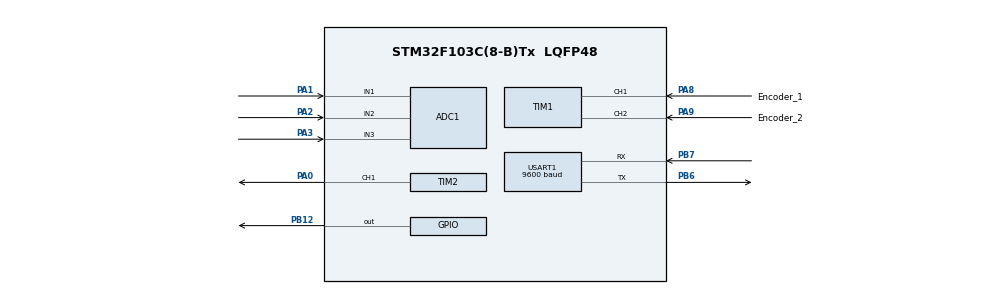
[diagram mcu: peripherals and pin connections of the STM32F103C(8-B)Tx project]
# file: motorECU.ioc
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ADC1.Channel-1\#ChannelRegularConversion=ADC_CHANNEL_1
ADC1.Channel-2\#ChannelRegularConversion=ADC_CHANNEL_2
ADC1.Channel-3\#ChannelRegularConversion=ADC_CHANNEL_3
ADC1.ContinuousConvMode=DISABLE
ADC1.NbrOfConversion=3
ADC1.NbrOfConversionFlag=1
ADC1.Rank-1\#ChannelRegularConversion=1
ADC1.Rank-2\#ChannelRegularConversion=2
ADC1.Rank-3\#ChannelRegularConversion=3
ADC1.SamplingTime-1\#ChannelRegularConversion=ADC_SAMPLETIME_1CYCLE_5
ADC1.SamplingTime-2\#ChannelRegularConversion=ADC_SAMPLETIME_1CYCLE_5
ADC1.SamplingTime-3\#ChannelRegularConversion=ADC_SAMPLETIME_1CYCLE_5
ADC1.master=1
Dma.ADC1.0.Direction=DMA_PERIPH_TO_MEMORY
Dma.ADC1.0.Instance=DMA1_Channel1
Dma.ADC1.0.MemDataAlignment=DMA_MDATAALIGN_WORD
Dma.ADC1.0.MemInc=DMA_MINC_ENABLE
Dma.ADC1.0.Mode=DMA_CIRCULAR
Dma.ADC1.0.PeriphDataAlignment=DMA_PDATAALIGN_WORD
Dma.ADC1.0.PeriphInc=DMA_PINC_DISABLE
Dma.ADC1.0.Priority=DMA_PRIORITY_LOW
Dma.Request0=ADC1
Mcu.Family=STM32F1
Mcu.Name=STM32F103C(8-B)Tx
Mcu.Package=LQFP48
NVIC.DMA1_Channel1_IRQn=true\:0\:0\:false\:false\:true\:false\:true\:true
NVIC.PriorityGroup=NVIC_PRIORITYGROUP_4
PA0-WKUP.Signal=S_TIM2_CH1_ETR
PA1.Signal=ADCx_IN1
PA13.Mode=Serial_Wire
PA13.Signal=SYS_JTMS-SWDIO
PA14.Mode=Serial_Wire
PA14.Signal=SYS_JTCK-SWCLK
PA2.Signal=ADCx_IN2
PA3.Signal=ADCx_IN3
PA8.GPIO_Label=Encoder_1
PA8.Signal=S_TIM1_CH1
PA9.GPIO_Label=Encoder_2
PA9.Signal=S_TIM1_CH2
PB12.Signal=GPIO_Output
PB6.Mode=Asynchronous
PB6.Signal=USART1_TX
PB7.Mode=Asynchronous
PB7.Signal=USART1_RX
ProjectManager.HeapSize=0x200
ProjectManager.StackSize=0x400
ProjectManager.TargetToolchain=STM32CubeIDE
RCC.APB1Freq_Value=8000000
RCC.APB2Freq_Value=8000000
SH.ADCx_IN1.0=ADC1_IN1,IN1
SH.ADCx_IN2.0=ADC1_IN2,IN2
SH.ADCx_IN3.0=ADC1_IN3,IN3
SH.S_TIM1_CH1.0=TIM1_CH1,Encoder_Interface
SH.S_TIM1_CH2.0=TIM1_CH2,Encoder_Interface
SH.S_TIM2_CH1_ETR.0=TIM2_CH1,PWM Generation1 CH1
TIM2.Channel-PWM\ Generation1\ CH1=TIM_CHANNEL_1
USART1.BaudRate=9600
USART1.VirtualMode=VM_ASYNC
VP_TIM2_VS_ClockSourceINT.Mode=Internal
board=custom

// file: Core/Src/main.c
/* USER CODE BEGIN Header */
/**
  ******************************************************************************
  * @file           : main.c
  * @brief          : Main program body
  ******************************************************************************
  * @attention
  *
  * Copyright (c) 2024 STMicroelectronics.
  * All rights reserved.
  *
  * This software is licensed under terms that can be found in the LICENSE file
  * in the root directory of this software component.
  * If no LICENSE file comes with this software, it is provided AS-IS.
  *
  ******************************************************************************
  */
/* USER CODE END Header */
#include "main.h"

/* USER CODE BEGIN Includes */
#include "DC_MOTOR.h"
#include "Pedal.h"

#include "Encoder.h"
#include "Comm.h"
#include <stdio.h>
#include "Indicators.h"

#include "Schedular.h"

/* USER CODE END Includes */

ADC_HandleTypeDef hadc1;
DMA_HandleTypeDef hdma_adc1;

TIM_HandleTypeDef htim1;
TIM_HandleTypeDef htim2;

UART_HandleTypeDef huart1;

void SystemClock_Config(void);
static void MX_GPIO_Init(void);
static void MX_DMA_Init(void);
static void MX_USART1_UART_Init(void);
static void MX_TIM2_Init(void);
static void MX_ADC1_Init(void);
static void MX_TIM1_Init(void);

/* USER CODE BEGIN 0 */
void GetSwitchState_50MS_runnable(void)
  {
	volatile uint8_t read = INDICATORS_getPotValue(POT_PEDAL);
	INDICATORS_updatePotValues();
	read++;
	/*if(INDICATORS_isButtonPressed(BUTTON_MOTOR))
	{
		HAL_GPIO_TogglePin(GPIOB, GPIO_PIN_13);
	}
    /*if(SWITCH_getStateAsync(BUTTON_MOTOR) == SWITCH_PRESSED)
    {
    	HAL_GPIO_WritePin(GPIOB, GPIO_PIN_13, GPIO_PIN_SET);
    }
    else if(SWITCH_getStateAsync(BUTTON_MOTOR) == SWITCH_RELEASED)
    {
    	HAL_GPIO_WritePin(GPIOB, GPIO_PIN_13, GPIO_PIN_RESET);
    }*/
  }
/* USER CODE END 0 */

int main(void)
{

  /* MCU Configuration--------------------------------------------------------*/

  /* Reset of all peripherals, Initializes the Flash interface and the Systick. */

	HAL_Init();

  /* Configure the system clock */
  SystemClock_Config();

  /* Initialize all configured peripherals */
  MX_GPIO_Init();
  MX_DMA_Init();
  MX_USART1_UART_Init();
  MX_TIM2_Init();
  MX_ADC1_Init();
  MX_TIM1_Init();
  /* USER CODE BEGIN 2 */
  DC_MOTOR_Init(0);
  DC_MOTOR_Start(0, DIR_CCW, 0);
  /* USER CODE END 2 */

  /* Infinite loop */
  /* USER CODE BEGIN WHILE */
  HAL_ADC_Start(&hadc1);
  Comm_Init(COMM_UART);
  Encoder_Init(&htim1);
  INDICATORS_init();

  sched_init();
  sched_start();

  while (1)
  {

    /* USER CODE END WHILE */

  }
}

void SystemClock_Config(void)
{
  RCC_OscInitTypeDef RCC_OscInitStruct = {0};
  RCC_ClkInitTypeDef RCC_ClkInitStruct = {0};
  RCC_PeriphCLKInitTypeDef PeriphClkInit = {0};

  /** Initializes the RCC Oscillators according to the specified parameters
  * in the RCC_OscInitTypeDef structure.
  */
  RCC_OscInitStruct.OscillatorType = RCC_OSCILLATORTYPE_HSI;
  RCC_OscInitStruct.HSIState = RCC_HSI_ON;
  RCC_OscInitStruct.HSICalibrationValue = RCC_HSICALIBRATION_DEFAULT;
  RCC_OscInitStruct.PLL.PLLState = RCC_PLL_NONE;
  if (HAL_RCC_OscConfig(&RCC_OscInitStruct) != HAL_OK)
  {
    Error_Handler();
  }

  /** Initializes the CPU, AHB and APB buses clocks
  */
  RCC_ClkInitStruct.ClockType = RCC_CLOCKTYPE_HCLK|RCC_CLOCKTYPE_SYSCLK
                              |RCC_CLOCKTYPE_PCLK1|RCC_CLOCKTYPE_PCLK2;
  RCC_ClkInitStruct.SYSCLKSource = RCC_SYSCLKSOURCE_HSI;
  RCC_ClkInitStruct.AHBCLKDivider = RCC_SYSCLK_DIV1;
  RCC_ClkInitStruct.APB1CLKDivider = RCC_HCLK_DIV1;
  RCC_ClkInitStruct.APB2CLKDivider = RCC_HCLK_DIV1;

  if (HAL_RCC_ClockConfig(&RCC_ClkInitStruct, FLASH_LATENCY_0) != HAL_OK)
  {
    Error_Handler();
  }
  PeriphClkInit.PeriphClockSelection = RCC_PERIPHCLK_ADC;
  PeriphClkInit.AdcClockSelection = RCC_ADCPCLK2_DIV2;
  if (HAL_RCCEx_PeriphCLKConfig(&PeriphClkInit) != HAL_OK)
  {
    Error_Handler();
  }
}

static void MX_ADC1_Init(void)
{

  ADC_ChannelConfTypeDef sConfig = {0};

  /** Common config
  */
  hadc1.Instance = ADC1;
  hadc1.Init.ScanConvMode = ADC_SCAN_ENABLE;
  hadc1.Init.ContinuousConvMode = DISABLE;
  hadc1.Init.DiscontinuousConvMode = DISABLE;
  hadc1.Init.ExternalTrigConv = ADC_SOFTWARE_START;
  hadc1.Init.DataAlign = ADC_DATAALIGN_RIGHT;
  hadc1.Init.NbrOfConversion = 3;
  if (HAL_ADC_Init(&hadc1) != HAL_OK)
  {
    Error_Handler();
  }

  /** Configure Regular Channel
  */
  sConfig.Channel = ADC_CHANNEL_1;
  sConfig.Rank = ADC_REGULAR_RANK_1;
  sConfig.SamplingTime = ADC_SAMPLETIME_1CYCLE_5;
  if (HAL_ADC_ConfigChannel(&hadc1, &sConfig) != HAL_OK)
  {
    Error_Handler();
  }

  /** Configure Regular Channel
  */
  sConfig.Channel = ADC_CHANNEL_2;
  sConfig.Rank = ADC_REGULAR_RANK_2;
  if (HAL_ADC_ConfigChannel(&hadc1, &sConfig) != HAL_OK)
  {
    Error_Handler();
  }

  /** Configure Regular Channel
  */
  sConfig.Channel = ADC_CHANNEL_3;
  sConfig.Rank = ADC_REGULAR_RANK_3;
  if (HAL_ADC_ConfigChannel(&hadc1, &sConfig) != HAL_OK)
  {
    Error_Handler();
  }

}

static void MX_TIM1_Init(void)
{

  TIM_Encoder_InitTypeDef sConfig = {0};
  TIM_MasterConfigTypeDef sMasterConfig = {0};

  htim1.Instance = TIM1;
  htim1.Init.Prescaler = 0;
  htim1.Init.CounterMode = TIM_COUNTERMODE_UP;
  htim1.Init.Period = 65535;
  htim1.Init.ClockDivision = TIM_CLOCKDIVISION_DIV1;
  htim1.Init.RepetitionCounter = 0;
  htim1.Init.AutoReloadPreload = TIM_AUTORELOAD_PRELOAD_DISABLE;
  sConfig.EncoderMode = TIM_ENCODERMODE_TI1;
  sConfig.IC1Polarity = TIM_ICPOLARITY_RISING;
  sConfig.IC1Selection = TIM_ICSELECTION_DIRECTTI;
  sConfig.IC1Prescaler = TIM_ICPSC_DIV1;
  sConfig.IC1Filter = 0;
  sConfig.IC2Polarity = TIM_ICPOLARITY_RISING;
  sConfig.IC2Selection = TIM_ICSELECTION_DIRECTTI;
  sConfig.IC2Prescaler = TIM_ICPSC_DIV1;
  sConfig.IC2Filter = 0;
  if (HAL_TIM_Encoder_Init(&htim1, &sConfig) != HAL_OK)
  {
    Error_Handler();
  }
  sMasterConfig.MasterOutputTrigger = TIM_TRGO_RESET;
  sMasterConfig.MasterSlaveMode = TIM_MASTERSLAVEMODE_DISABLE;
  if (HAL_TIMEx_MasterConfigSynchronization(&htim1, &sMasterConfig) != HAL_OK)
  {
    Error_Handler();
  }

}

static void MX_TIM2_Init(void)
{

  TIM_ClockConfigTypeDef sClockSourceConfig = {0};
  TIM_MasterConfigTypeDef sMasterConfig = {0};
  TIM_OC_InitTypeDef sConfigOC = {0};

  htim2.Instance = TIM2;
  htim2.Init.Prescaler = 0;
  htim2.Init.CounterMode = TIM_COUNTERMODE_UP;
  htim2.Init.Period = 65535;
  htim2.Init.ClockDivision = TIM_CLOCKDIVISION_DIV1;
  htim2.Init.AutoReloadPreload = TIM_AUTORELOAD_PRELOAD_DISABLE;
  if (HAL_TIM_Base_Init(&htim2) != HAL_OK)
  {
    Error_Handler();
  }
  sClockSourceConfig.ClockSource = TIM_CLOCKSOURCE_INTERNAL;
  if (HAL_TIM_ConfigClockSource(&htim2, &sClockSourceConfig) != HAL_OK)
  {
    Error_Handler();
  }
  if (HAL_TIM_PWM_Init(&htim2) != HAL_OK)
  {
    Error_Handler();
  }
  sMasterConfig.MasterOutputTrigger = TIM_TRGO_RESET;
  sMasterConfig.MasterSlaveMode = TIM_MASTERSLAVEMODE_DISABLE;
  if (HAL_TIMEx_MasterConfigSynchronization(&htim2, &sMasterConfig) != HAL_OK)
  {
    Error_Handler();
  }
  sConfigOC.OCMode = TIM_OCMODE_PWM1;
  sConfigOC.Pulse = 0;
  sConfigOC.OCPolarity = TIM_OCPOLARITY_HIGH;
  sConfigOC.OCFastMode = TIM_OCFAST_DISABLE;
  if (HAL_TIM_PWM_ConfigChannel(&htim2, &sConfigOC, TIM_CHANNEL_1) != HAL_OK)
  {
    Error_Handler();
  }
  HAL_TIM_MspPostInit(&htim2);

}

static void MX_USART1_UART_Init(void)
{

  huart1.Instance = USART1;
  huart1.Init.BaudRate = 9600;
  huart1.Init.WordLength = UART_WORDLENGTH_8B;
  huart1.Init.StopBits = UART_STOPBITS_1;
  huart1.Init.Parity = UART_PARITY_NONE;
  huart1.Init.Mode = UART_MODE_TX_RX;
  huart1.Init.HwFlowCtl = UART_HWCONTROL_NONE;
  huart1.Init.OverSampling = UART_OVERSAMPLING_16;
  if (HAL_UART_Init(&huart1) != HAL_OK)
  {
    Error_Handler();
  }

}

static void MX_DMA_Init(void)
{

  /* DMA controller clock enable */
  __HAL_RCC_DMA1_CLK_ENABLE();

  /* DMA interrupt init */
  /* DMA1_Channel1_IRQn interrupt configuration */
  HAL_NVIC_SetPriority(DMA1_Channel1_IRQn, 0, 0);
  HAL_NVIC_EnableIRQ(DMA1_Channel1_IRQn);

}

static void MX_GPIO_Init(void)
{
  GPIO_InitTypeDef GPIO_InitStruct = {0};

  /* GPIO Ports Clock Enable */
  __HAL_RCC_GPIOA_CLK_ENABLE();
  __HAL_RCC_GPIOB_CLK_ENABLE();

  /*Configure GPIO pin Output Level */
  HAL_GPIO_WritePin(GPIOB, GPIO_PIN_13, GPIO_PIN_RESET);

  /*Configure GPIO pin : PB12 */
  GPIO_InitStruct.Pin = GPIO_PIN_12;
  GPIO_InitStruct.Mode = GPIO_MODE_INPUT;
  GPIO_InitStruct.Pull = GPIO_PULLUP;
  HAL_GPIO_Init(GPIOB, &GPIO_InitStruct);

  /*Configure GPIO pin : PB13 */
  GPIO_InitStruct.Pin = GPIO_PIN_13;
  GPIO_InitStruct.Mode = GPIO_MODE_OUTPUT_PP;
  GPIO_InitStruct.Pull = GPIO_NOPULL;
  GPIO_InitStruct.Speed = GPIO_SPEED_FREQ_LOW;
  HAL_GPIO_Init(GPIOB, &GPIO_InitStruct);

}

void Error_Handler(void)
{
  __disable_irq();
  while (1)
  {
  }
}
